# RL6678_IP_SVD register map
Vendor: Realtek
Registers are 32-bit, read-write, reset 0x0 unless marked. A register's access mark holds for its fields unless they carry their own. Offsets are from the block's base; [hi:lo] are bit positions; {n}, {i} and the like mark numbered series.

## PLL_REG
Base 0x42008840
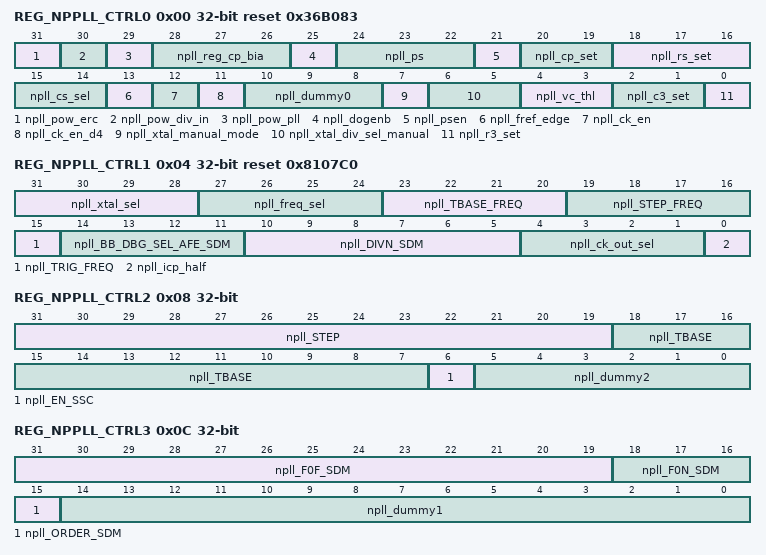
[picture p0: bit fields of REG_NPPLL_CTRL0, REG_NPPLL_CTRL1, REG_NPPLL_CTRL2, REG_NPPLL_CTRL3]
0x00 REG_NPPLL_CTRL0 reset 0x36B083
  [31] npll_pow_erc — erc enable. 0 -> 1
  [30] npll_pow_div_in — input divider enable (need pwl signal) 0 -> 1
  [29] npll_pow_pll — (need pwl signal) 0 -> 1
  [28:26] npll_reg_cp_bia — charge pump current selection . Default=10uA CP current select : 000: Icp=10uA, 001: Icp=15uA, 010: Icp=20uA, 011: Icp=25uA; 100: Icp=30uA, 101: Icp=35uA, 110: Icp=40uA, 111: Icp=450uA;
  [25] npll_dogenb — 0: watch dog on, 1: watch dog off
  [24:22] npll_ps
  [21] npll_psen — phase selector enable
  [20:19] npll_cp_set — Cp selection. Default=6p 00: Cp=4p, 01: Cp=5p, 10: Cp=6p, 11: Cp=7p 40M = 6p(10), 26M = 6p(10)
  [18:16] npll_rs_set — Rs selection. Default=5k 000: Rs=15k, 001: Rs=13k, 010: Rs=11k, 011: Rs=9k, 100: Rs=7k, 101: Rs=5k, 110: Rs=3k, 111: Rs=1k; 40M = 3k(110), 26M = 3k(110)
  [15:14] npll_cs_sel — Cs selection. Default=60p 00: Cs=40p, 01: Cs=50p, 10: Cs=60p, 11: Cs=70p 40M = 60p(10), 26M = 60p(10)
  [13] npll_fref_edge — 0:fref, 1:frefb
  [12] npll_ck_en — output clk enable
  [11] npll_ck_en_d4 — output clk div 4 enable
  [10:8] npll_dummy0 — HW used only , these are for reserved
  [7] npll_xtal_manual_mode — reg_xtal_maunal_mode. Default=0 0: reg_xtal_sel<3:0> is controlled by REG, xtal_div_sel is controlled by mapping table. 1: reg_xtal_sel<3:0>=4'b1111, xtal_div_sel is controlled by reg_xtal_div_sel_maunal<1:0>
  [6:5] npll_xtal_div_sel_manual — input divider selection in xtal maunal mode. Default=00 00=/1, 10=/2, 11=/4
  [4:3] npll_vc_thl — VC voltage, Default=00 00: VC=1/4Vdd, 01: VC=1/2Vdd, 10=3/4Vdd, 11: VC=Vdd
  [2:1] npll_c3_set — C3 selection. Default=1p 00: 0.5p, 01: 1p, 10: Cs=1.5p, 11: 2p
  [0] npll_r3_set — Rs selection. Default=1k 0: 0 Ohm, 1: 1k Ohm
0x04 REG_NPPLL_CTRL1 reset 0x8107C0
  [31:28] npll_xtal_sel — xtal selection, Default=40MHz 0000= 40MHz, 0001= 25MHz, 0010= 13MHz, 0011= 19.2MHz 0100= 20MHz, 0101= 26MHz, 0110= 38.4MHz, 0111= 17.664MHz 1000= 16MHz, 1001= 14.138MHz, 1010= 12MHz, 1011= 52MHz 1100= 48MHz, 1101= 27MHz, 1110= 24MHz, 1111= none
  [27:24] npll_freq_sel — output clk selection, Default=400MHz 0000= 400MHz, 0001= X, 0010= X, 0011= X, 0100= 216MHz, 0101=196.608MHz, 0110=192MHz, 0111= 180.632MHz, 1000= 148.5MHz,1001= X, 1010= X, 1011= X, 1100= X, 1101= X, 1110= X, 1111= 500MHz
  [23:20] npll_TBASE_FREQ — now is empty
  [19:16] npll_STEP_FREQ — step size selection for switching freq. 0000: 2^5 0001: 2^6 0010: 2^7 0011: 2^8 0100: 2^9 0101: 2^10 0110: 2^11 0111: 2^12
  [15] npll_TRIG_FREQ — freq. step up or step down enable
  [14:11] npll_BB_DBG_SEL_AFE_SDM
  [10:5] npll_DIVN_SDM — 600M 40M: 001101 26M: 010101
  [4:1] npll_ck_out_sel — output divider selection. Default=0000(/1) 0000=/1, 1000=/2, 1100=/8, 1110=/16, 1111=/32
  [0] npll_icp_half — charge pump current half or not 0: no half 1: half
0x08 REG_NPPLL_CTRL2
  [31:19] npll_STEP — ssc step size selection.
  [18:7] npll_TBASE — ssc freq selection
  [6] npll_EN_SSC — ssc enable. Default=0
  [5:0] npll_dummy2 — HW used only , these are for reserved
0x0C REG_NPPLL_CTRL3
  [31:19] npll_F0F_SDM — 600M 40M: 0 0000 0000 0000 26M: 1 0011 1011 0001
  [18:16] npll_F0N_SDM — 600M 40M: 000 26M: 000
  [15] npll_ORDER_SDM — SDM order
  [14:0] npll_dummy1 — HW used only , these are for reserved
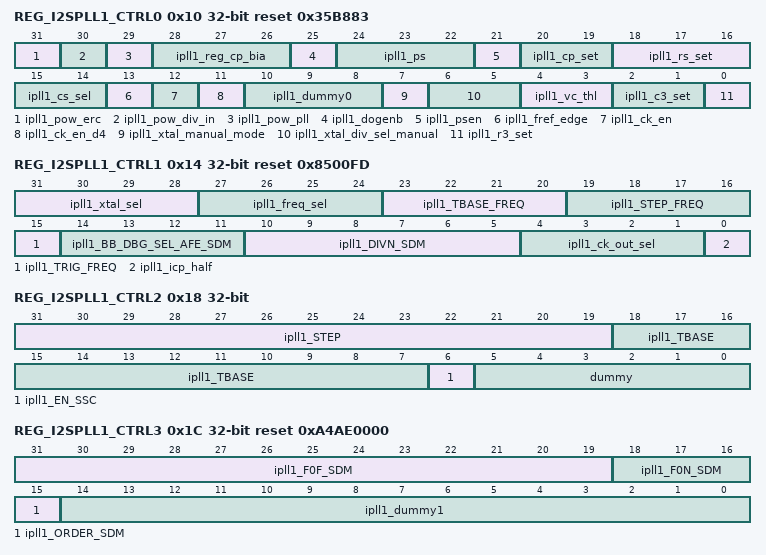
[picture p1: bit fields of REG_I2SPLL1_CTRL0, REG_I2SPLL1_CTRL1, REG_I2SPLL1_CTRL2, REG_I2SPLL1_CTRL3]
0x10 REG_I2SPLL1_CTRL0 reset 0x35B883
  [31] ipll1_pow_erc — erc enable. 0 -> 1
  [30] ipll1_pow_div_in — input divider enable (need pwl signal) 0 -> 1
  [29] ipll1_pow_pll — (need pwl signal) 0 -> 1
  [28:26] ipll1_reg_cp_bia — charge pump current selection . Default=10uA CP current select : 000: Icp=10uA, 001: Icp=15uA, 010: Icp=20uA, 011: Icp=25uA; 100: Icp=30uA, 101: Icp=35uA, 110: Icp=40uA, 111: Icp=450uA;
  [25] ipll1_dogenb — 0: watch dog on, 1: watch dog off
  [24:22] ipll1_ps — phase select
  [21] ipll1_psen — phase selector enable
  [20:19] ipll1_cp_set — Cp selection. Default=6p 00: Cp=4p, 01: Cp=5p, 10: Cp=6p, 11: Cp=7p 40M = 6p(10), 26M = 6p(10)
  [18:16] ipll1_rs_set — Rs selection. Default=5k 000: Rs=15k, 001: Rs=13k, 010: Rs=11k, 011: Rs=9k, 100: Rs=7k, 101: Rs=5k, 110: Rs=3k, 111: Rs=1k; 40M = 5k(101), 26M = 5k(101)
  [15:14] ipll1_cs_sel — Cs selection. Default=60p 00: Cs=40p, 01: Cs=50p, 10: Cs=60p, 11: Cs=70p 40M = 60p(10), 26M = 60p(10)
  [13] ipll1_fref_edge — 0:fref, 1:frefb
  [12] ipll1_ck_en — output clk enable
  [11] ipll1_ck_en_d4 — output clk div 4 enable
  [10:8] ipll1_dummy0 — HW used only , these are for reserved
  [7] ipll1_xtal_manual_mode — reg_xtal_maunal_mode. Default=0 0: reg_xtal_sel<3:0> is controlled by REG, xtal_div_sel is controlled by mapping table. 1: reg_xtal_sel<3:0>=4'b1111, xtal_div_sel is controlled by reg_xtal_div_sel_maunal<1:0>
  [6:5] ipll1_xtal_div_sel_manual — input divider selection in xtal maunal mode. Default=00 00=/1, 10=/2, 11=/4
  [4:3] ipll1_vc_thl — VC voltage, Default=00 00: VC=1/4Vdd, 01: VC=1/2Vdd, 10=3/4Vdd, 11: VC=Vdd
  [2:1] ipll1_c3_set — C3 selection. Default=1p 00: 0.5p, 01: 1p, 10: Cs=1.5p, 11: 2p
  [0] ipll1_r3_set — Rs selection. Default=1k 0: 0 Ohm, 1: 1k Ohm
0x14 REG_I2SPLL1_CTRL1 reset 0x8500FD
  [31:28] ipll1_xtal_sel — xtal selection, Default=40MHz 0000= 40MHz, 0001= 25MHz, 0010= 13MHz, 0011= 19.2MHz 0100= 20MHz, 0101= 26MHz, 0110= 38.4MHz, 0111= 17.664MHz 1000= 16MHz, 1001= 14.138MHz, 1010= 12MHz, 1011= 52MHz 1100= 48MHz, 1101= 27MHz, 1110= 24MHz, 1111= none
  [27:24] ipll1_freq_sel — output clk selection, Default=400MHz 0000= 400MHz, 0001= X, 0010= X, 0011= X, 0100= 216MHz, 0101=196.608MHz, 0110=192MHz, 0111= 180.632MHz, 1000= 148.5MHz,1001= X, 1010= X, 1011= X, 1100= X, 1101= X, 1110= X, 1111= 500MHz
  [23:20] ipll1_TBASE_FREQ — now is empty
  [19:16] ipll1_STEP_FREQ — step size selection for switching freq. 0000: 2^5 0001: 2^6 0010: 2^7 0011: 2^8 0100: 2^9 0101: 2^10 0110: 2^11 0111: 2^12
  [15] ipll1_TRIG_FREQ — freq. step up or step down enable
  [14:11] ipll1_BB_DBG_SEL_AFE_SDM
  [10:5] ipll1_DIVN_SDM — 393.216M (98.304M / 24.576M) 40M: 000111 26M: 001101
  [4:1] ipll1_ck_out_sel — output divider selection. Default=1110(/16) 0000=/1, 1000=/2, 1100=/8, 1110=/16, 1111=/32
  [0] ipll1_icp_half — charge pump current half or not 0: no half 1: half
0x18 REG_I2SPLL1_CTRL2
  [31:19] ipll1_STEP — ssc step size selection.
  [18:7] ipll1_TBASE — ssc freq selection
  [6] ipll1_EN_SSC — ssc enable. Default=0
  [5:0] dummy — HW used only , these are for reserved
0x1C REG_I2SPLL1_CTRL3 reset 0xA4AE0000
  [31:19] ipll1_F0F_SDM — 393.216M (98.304M / 24.576M) 40M: 1 0100 1001 0101 26M: 1 1111 1010 1010
  [18:16] ipll1_F0N_SDM — 393.216M (98.304M / 24.576M) 40M: 110 26M: 000
  [15] ipll1_ORDER_SDM — SDM order
  [14:0] ipll1_dummy1 — HW used only , these are for reserved
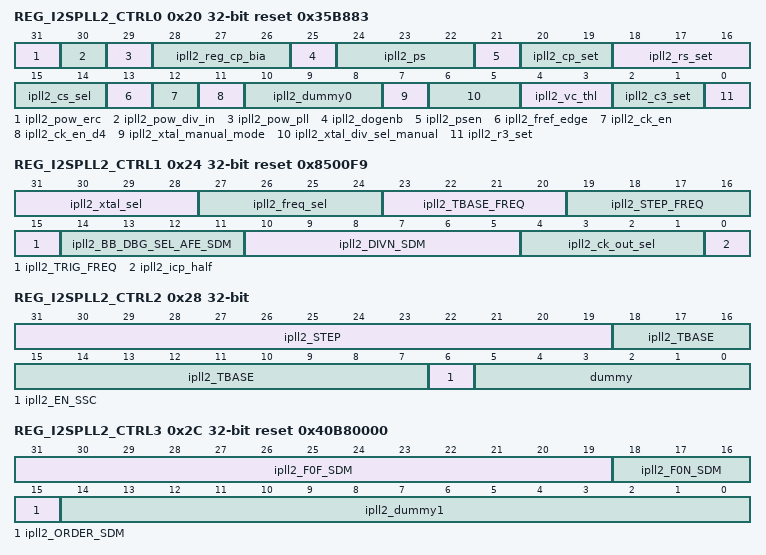
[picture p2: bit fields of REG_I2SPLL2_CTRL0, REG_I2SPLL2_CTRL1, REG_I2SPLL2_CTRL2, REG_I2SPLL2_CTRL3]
0x20 REG_I2SPLL2_CTRL0 reset 0x35B883
  [31] ipll2_pow_erc — erc enable. 0 -> 1
  [30] ipll2_pow_div_in — input divider enable (need pwl signal) 0 -> 1
  [29] ipll2_pow_pll — (need pwl signal) 0 -> 1
  [28:26] ipll2_reg_cp_bia — charge pump current selection . Default=10uA CP current select : 000: Icp=10uA, 001: Icp=15uA, 010: Icp=20uA, 011: Icp=25uA; 100: Icp=30uA, 101: Icp=35uA, 110: Icp=40uA, 111: Icp=450uA;
  [25] ipll2_dogenb — 0: watch dog on, 1: watch dog off
  [24:22] ipll2_ps — phase select
  [21] ipll2_psen — phase selector enable
  [20:19] ipll2_cp_set — Cp selection. Default=6p 00: Cp=4p, 01: Cp=5p, 10: Cp=6p, 11: Cp=7p 40M = 6p(10), 26M = 6p(10)
  [18:16] ipll2_rs_set — Rs selection. Default=5k 000: Rs=15k, 001: Rs=13k, 010: Rs=11k, 011: Rs=9k, 100: Rs=7k, 101: Rs=5k, 110: Rs=3k, 111: Rs=1k; 40M = 5k(101), 26M = 5k(101)
  [15:14] ipll2_cs_sel — Cs selection. Default=60p 00: Cs=40p, 01: Cs=50p, 10: Cs=60p, 11: Cs=70p 40M = 60p(10), 26M = 60p(10)
  [13] ipll2_fref_edge — 0:fref, 1:frefb
  [12] ipll2_ck_en — output clk enable
  [11] ipll2_ck_en_d4 — output clk div 4 enable
  [10:8] ipll2_dummy0 — HW used only , these are for reserved
  [7] ipll2_xtal_manual_mode — reg_xtal_maunal_mode. Default=0 0: reg_xtal_sel<3:0> is controlled by REG, xtal_div_sel is controlled by mapping table. 1: reg_xtal_sel<3:0>=4'b1111, xtal_div_sel is controlled by reg_xtal_div_sel_maunal<1:0>
  [6:5] ipll2_xtal_div_sel_manual — input divider selection in xtal maunal mode. Default=00 00=/1, 10=/2, 11=/4
  [4:3] ipll2_vc_thl — VC voltage, Default=00 00: VC=1/4Vdd, 01: VC=1/2Vdd, 10=3/4Vdd, 11: VC=Vdd
  [2:1] ipll2_c3_set — C3 selection. Default=1p 00: 0.5p, 01: 1p, 10: Cs=1.5p, 11: 2p
  [0] ipll2_r3_set — Rs selection. Default=1k 0: 0 Ohm, 1: 1k Ohm
0x24 REG_I2SPLL2_CTRL1 reset 0x8500F9
  [31:28] ipll2_xtal_sel — xtal selection, Default=40MHz 0000= 40MHz, 0001= 25MHz, 0010= 13MHz, 0011= 19.2MHz 0100= 20MHz, 0101= 26MHz, 0110= 38.4MHz, 0111= 17.664MHz 1000= 16MHz, 1001= 14.138MHz, 1010= 12MHz, 1011= 52MHz 1100= 48MHz, 1101= 27MHz, 1110= 24MHz, 1111= none
  [27:24] ipll2_freq_sel — output clk selection, Default=400MHz 0000= 400MHz, 0001= X, 0010= X, 0011= X, 0100= 216MHz, 0101=196.608MHz, 0110=192MHz, 0111= 180.632MHz, 1000= 148.5MHz,1001= X, 1010= X, 1011= X, 1100= X, 1101= X, 1110= X, 1111= 500MHz
  [23:20] ipll2_TBASE_FREQ — now is empty
  [19:16] ipll2_STEP_FREQ — step size selection for switching freq. 0000: 2^5 0001: 2^6 0010: 2^7 0011: 2^8 0100: 2^9 0101: 2^10 0110: 2^11 0111: 2^12
  [15] ipll2_TRIG_FREQ — freq. step up or step down enable
  [14:11] ipll2_BB_DBG_SEL_AFE_SDM
  [10:5] ipll2_DIVN_SDM — 361.264M (45.158M) 40M: 000111 26M: 001101
  [4:1] ipll2_ck_out_sel — output divider selection. Default=1100(/8) 0000=/1, 1000=/2, 1100=/8, 1110=/16, 1111=/32
  [0] ipll2_icp_half — charge pump current half or not 0: no half 1: half
0x28 REG_I2SPLL2_CTRL2
  [31:19] ipll2_STEP — ssc step size selection.
  [18:7] ipll2_TBASE — ssc freq selection
  [6] ipll2_EN_SSC — ssc enable. Default=0
  [5:0] dummy — HW used only , these are for reserved
0x2C REG_I2SPLL2_CTRL3 reset 0x40B80000
  [31:19] ipll2_F0F_SDM — 361.264M (45.158M) 40M: 0 1000 0001 0111 26M: 0 0101 0001 0000
  [18:16] ipll2_F0N_SDM — 361.264M (45.158M) 40M: 000 26M: 111
  [15] ipll2_ORDER_SDM — SDM order
  [14:0] ipll2_dummy1 — HW used only , these are for reserved
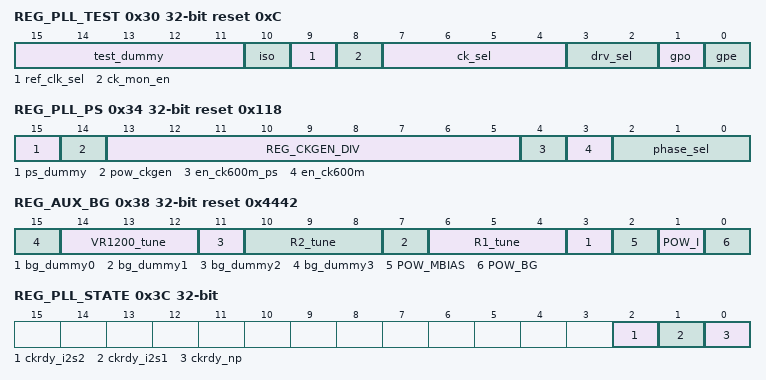
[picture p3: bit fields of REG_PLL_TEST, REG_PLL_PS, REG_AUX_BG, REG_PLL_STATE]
0x30 REG_PLL_TEST reset 0xC
  [15:11] test_dummy — HW used only , these are for reserved
  [10] iso — 1 for ISO ck_fref/ck_frefb
  [9] ref_clk_sel — xtal clk from 0 special route 1 APR
  [8] ck_mon_en — ckmon enable
  [7:4] ck_sel — ckmon clk sel 1111:CK_400M_ISP 1110:READY_400M 1101:CK_ISPS 1100:READY_ISPS 1011:CK_300M_SYS 1010:READY_300M 1001:CK_240M_ENC 1000:READY_240M_ENC 0111:CK_80M_NP 0110:READY_80M_NP 0101:CK_98P304M_I2S 0100:CK_24P576M_I2S 0011:READY_I2S 0010:CK_45P158M_PCM 0001:READY_45P158M_PCM 0000:TL
  [3:2] drv_sel — AGPIO driving sel
  [1] gpo — AGPIO output enable
  [0] gpe — AGPIO enable
0x34 REG_PLL_PS reset 0x118
  [15] ps_dummy — HW used only , these are for reserved
  [14] pow_ckgen — pow of ckgen
  [13:5] REG_CKGEN_DIV — DIV9B , N=DIV<8:0>+2
  [4] en_ck600m_ps — enable shifted clk source for flash
  [3] en_ck600m — enable not shift clk source for flash
  [2:0] phase_sel — AGPIO driving sel
0x38 REG_AUX_BG reset 0x4442
  [4n+3] bg_dummy{n} (n=0..3) — HW used only , these are for reserved
  [14:12] VR1200_tune — Add 40k per step fine tune BG (Efuse)
  [10:8] R2_tune — Add 20k per step fine tune BG (Efuse)
  [6:4] R1_tune — Add 200k per step fine tune BG (Efuse)
  [2] POW_MBIAS — power on mbias
  [1] POW_I — power on BG current
  [0] POW_BG — power on BG
0x3C REG_PLL_STATE ro
  [2] ckrdy_i2s2 — I2S2 PLL clock is ready
  [1] ckrdy_i2s1 — I2S1 PLL clock is ready
  [0] ckrdy_np — NPLL clock is ready
